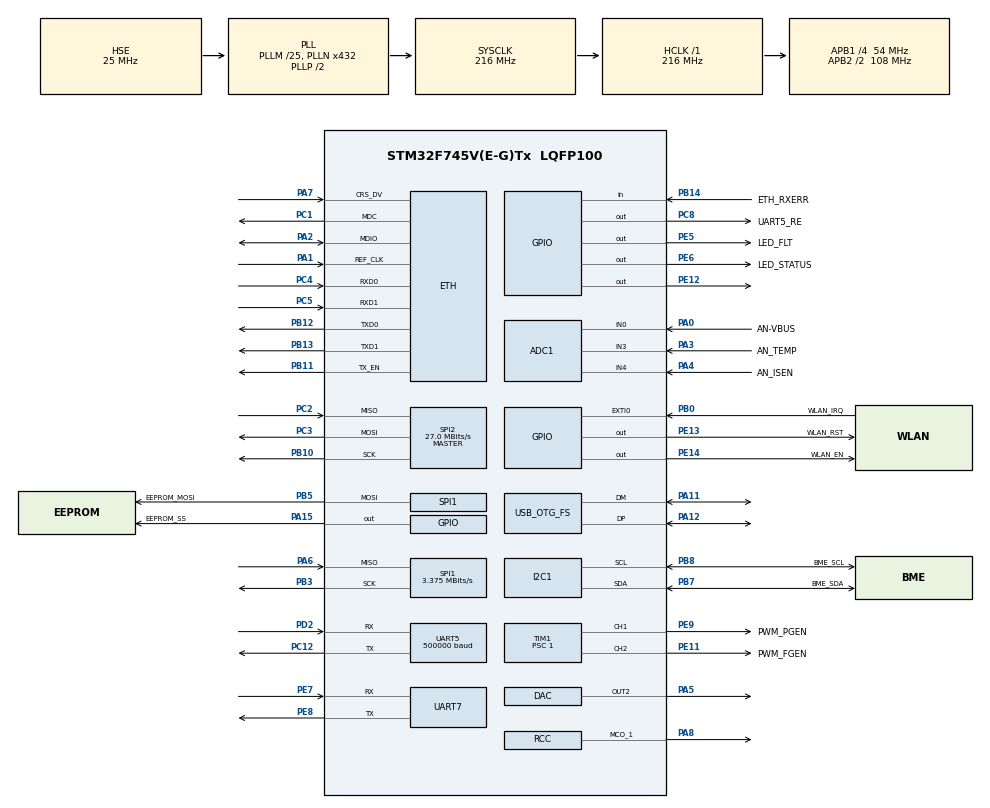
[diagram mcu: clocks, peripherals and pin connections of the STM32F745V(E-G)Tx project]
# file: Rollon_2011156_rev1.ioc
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ADC1.Channel-0\#ChannelRegularConversion=ADC_CHANNEL_0
ADC1.Channel-1\#ChannelRegularConversion=ADC_CHANNEL_3
ADC1.Channel-2\#ChannelRegularConversion=ADC_CHANNEL_4
ADC1.Channel-3\#ChannelRegularConversion=ADC_CHANNEL_TEMPSENSOR
ADC1.ContinuousConvMode=ENABLE
ADC1.DMAContinuousRequests=ENABLE
ADC1.EOCSelection=ADC_EOC_SEQ_CONV
ADC1.ExternalTrigConv=ADC_SOFTWARE_START
ADC1.InjNumberOfConversion=0
ADC1.NbrOfConversion=4
ADC1.NbrOfConversionFlag=1
ADC1.Rank-0\#ChannelRegularConversion=1
ADC1.Rank-1\#ChannelRegularConversion=2
ADC1.Rank-2\#ChannelRegularConversion=3
ADC1.Rank-3\#ChannelRegularConversion=4
ADC1.SamplingTime-0\#ChannelRegularConversion=ADC_SAMPLETIME_480CYCLES
ADC1.SamplingTime-1\#ChannelRegularConversion=ADC_SAMPLETIME_480CYCLES
ADC1.SamplingTime-2\#ChannelRegularConversion=ADC_SAMPLETIME_480CYCLES
ADC1.SamplingTime-3\#ChannelRegularConversion=ADC_SAMPLETIME_480CYCLES
ADC1.master=1
CORTEX_M7.ART_ACCELERATOR_ENABLE=0
CORTEX_M7.CPU_ICache=Enabled
CORTEX_M7.PREFETCH_ENABLE=0
CORTEX_M7.default_mode_Activation=0
Dma.ADC1.0.Direction=DMA_PERIPH_TO_MEMORY
Dma.ADC1.0.FIFOMode=DMA_FIFOMODE_DISABLE
Dma.ADC1.0.Instance=DMA2_Stream0
Dma.ADC1.0.MemDataAlignment=DMA_MDATAALIGN_HALFWORD
Dma.ADC1.0.MemInc=DMA_MINC_ENABLE
Dma.ADC1.0.Mode=DMA_CIRCULAR
Dma.ADC1.0.PeriphDataAlignment=DMA_PDATAALIGN_HALFWORD
Dma.ADC1.0.PeriphInc=DMA_PINC_DISABLE
Dma.ADC1.0.Priority=DMA_PRIORITY_LOW
Dma.Request0=ADC1
ETH.MACAddr=98\:80\:E1\:22\:00\:11
ETH.MediaInterface=HAL_ETH_RMII_MODE
I2C1.Analog_Filter=I2C_ANALOGFILTER_DISABLE
I2C1.Timing=0x00303D5D
LWIP.BSP.number=1
LWIP.GATEWAY_ADDRESS=192.168.010.001
LWIP.IP_ADDRESS=192.168.010.200
LWIP.LWIP_DHCP=0
LWIP.MEM_SIZE=4096
LWIP.NETMASK_ADDRESS=255.255.255.000
LWIP.PBUF_POOL_BUFSIZE=1560
LWIP.Version=v2.1.2_Cube
LWIP0.BSP.STBoard=false
LWIP0.BSP.api=BSP_COMPONENT_DRIVER
LWIP0.BSP.component=LAN8742
LWIP0.BSP.instance=LAN8742
LWIP0.BSP.name=Driver_PHY
LWIP0.BSP.semaphore=S_LAN8742
LWIP0.BSP.solution=LAN8742
Mcu.Family=STM32F7
Mcu.Name=STM32F745V(E-G)Tx
Mcu.Package=LQFP100
Mcu.UserConstants=PERIOD_T1,410;HPERIOD_T1,(PERIOD_T1/2);HPERIOD_PWR,((PERIOD_T1/10)*9)
NVIC.DMA2_Stream0_IRQn=true\:0\:0\:false\:false\:true\:false\:true\:true
NVIC.PriorityGroup=NVIC_PRIORITYGROUP_4
NVIC.TIM6_DAC_IRQn=true\:0\:0\:false\:false\:true\:true\:true\:true
NVIC.TIM7_IRQn=true\:0\:0\:false\:false\:true\:true\:true\:true
NVIC.UART5_IRQn=true\:0\:0\:false\:false\:true\:true\:true\:true
PA0/WKUP.GPIO_Label=AN-VBUS
PA0/WKUP.Signal=ADCx_IN0
PA1.Mode=RMII
PA1.Signal=ETH_REF_CLK
PA11.Mode=Device_Only
PA11.Signal=USB_OTG_FS_DM
PA12.Mode=Device_Only
PA12.Signal=USB_OTG_FS_DP
PA13.Mode=Serial_Wire
PA13.Signal=SYS_JTMS-SWDIO
PA14.Mode=Serial_Wire
PA14.Signal=SYS_JTCK-SWCLK
PA15.GPIO_Label=EEPROM_SS
PA15.Signal=GPIO_Output
PA2.Mode=RMII
PA2.Signal=ETH_MDIO
PA3.GPIO_Label=AN_TEMP
PA3.Signal=ADCx_IN3
PA4.GPIO_Label=AN_ISEN
PA4.Signal=ADCx_IN4
PA5.Signal=COMP_DAC2_group
PA6.Mode=Full_Duplex_Master
PA6.Signal=SPI1_MISO
PA7.Mode=RMII
PA7.Signal=ETH_CRS_DV
PA8.Mode=Clock-out-1
PA8.Signal=RCC_MCO_1
PB0.GPIO_Label=WLAN_IRQ
PB0.Signal=GPXTI0
PB10.Mode=Full_Duplex_Master
PB10.Signal=SPI2_SCK
PB11.Mode=RMII
PB11.Signal=ETH_TX_EN
PB12.Mode=RMII
PB12.Signal=ETH_TXD0
PB13.Mode=RMII
PB13.Signal=ETH_TXD1
PB14.GPIO_Label=ETH_RXERR
PB14.Signal=GPIO_Input
PB3.Mode=Full_Duplex_Master
PB3.Signal=SPI1_SCK
PB5.GPIO_Label=EEPROM_MOSI
PB5.Mode=Full_Duplex_Master
PB5.Signal=SPI1_MOSI
PB7.GPIO_Label=BME_SDA
PB7.Mode=I2C
PB7.Signal=I2C1_SDA
PB8.GPIO_Label=BME_SCL
PB8.Mode=I2C
PB8.Signal=I2C1_SCL
PC1.Mode=RMII
PC1.Signal=ETH_MDC
PC12.Mode=Asynchronous
PC12.Signal=UART5_TX
PC2.Mode=Full_Duplex_Master
PC2.Signal=SPI2_MISO
PC3.Mode=Full_Duplex_Master
PC3.Signal=SPI2_MOSI
PC4.Mode=RMII
PC4.Signal=ETH_RXD0
PC5.Mode=RMII
PC5.Signal=ETH_RXD1
PC8.GPIO_Label=UART5_RE
PC8.Signal=GPIO_Output
PD2.Mode=Asynchronous
PD2.Signal=UART5_RX
PE11.GPIO_Label=PWM_FGEN
PE11.Signal=S_TIM1_CH2
PE12.Signal=GPIO_Output
PE13.GPIO_Label=WLAN_RST
PE13.Signal=GPIO_Output
PE14.GPIO_Label=WLAN_EN
PE14.Signal=GPIO_Output
PE5.GPIO_Label=LED_FLT
PE5.Signal=GPIO_Output
PE6.GPIO_Label=LED_STATUS
PE6.Signal=GPIO_Output
PE7.Mode=Asynchronous
PE7.Signal=UART7_RX
PE8.Mode=Asynchronous
PE8.Signal=UART7_TX
PE9.GPIO_Label=PWM_PGEN
PE9.Signal=S_TIM1_CH1
PH0/OSC_IN.Mode=HSE-External-Clock-Source
PH0/OSC_IN.Signal=RCC_OSC_IN
PH1/OSC_OUT.Mode=HSE-External-Clock-Source
PH1/OSC_OUT.Signal=RCC_OSC_OUT
ProjectManager.HeapSize=0x2000
ProjectManager.StackSize=0x4000
ProjectManager.TargetToolchain=STM32CubeIDE
RCC.AHBFreq_Value=216000000
RCC.APB1CLKDivider=RCC_HCLK_DIV4
RCC.APB1Freq_Value=54000000
RCC.APB1TimFreq_Value=108000000
RCC.APB2CLKDivider=RCC_HCLK_DIV2
RCC.APB2Freq_Value=108000000
RCC.APB2TimFreq_Value=216000000
RCC.CortexFreq_Value=216000000
RCC.HCLKFreq_Value=216000000
RCC.HSE_VALUE=25000000
RCC.HSI_VALUE=16000000
RCC.I2C1CLockSelection=RCC_I2C1CLKSOURCE_HSI
RCC.LSE_VALUE=32768
RCC.PLL48CLockSelection=RCC_CLK48SOURCE_PLLSAIP
RCC.PLLM=25
RCC.PLLN=432
RCC.PLLQ=8
RCC.PLLSAIP=RCC_PLLSAIP_DIV4
RCC.SYSCLKFreq_VALUE=216000000
RCC.SYSCLKSource=RCC_SYSCLKSOURCE_PLLCLK
RCC.UART5CLockSelection=RCC_UART5CLKSOURCE_SYSCLK
RCC.UART7CLockSelection=RCC_UART7CLKSOURCE_SYSCLK
RCC.USBFreq_Value=48000000
RCC.VCOOutputFreq_Value=432000000
SH.ADCx_IN0.0=ADC1_IN0,IN0
SH.ADCx_IN3.0=ADC1_IN3,IN3
SH.ADCx_IN4.0=ADC1_IN4,IN4
SH.COMP_DAC2_group.0=DAC_OUT2,DAC_OUT2
SH.S_TIM1_CH1.0=TIM1_CH1,PWM Generation1 CH1
SH.S_TIM1_CH2.0=TIM1_CH2,PWM Generation2 CH2
SPI1.BaudRatePrescaler=SPI_BAUDRATEPRESCALER_32
SPI1.CalculateBaudRate=3.375 MBits/s
SPI1.DataSize=SPI_DATASIZE_8BIT
SPI1.Direction=SPI_DIRECTION_2LINES
SPI1.Mode=SPI_MODE_MASTER
SPI1.VirtualType=VM_MASTER
SPI2.BaudRatePrescaler=SPI_BAUDRATEPRESCALER_2
SPI2.CalculateBaudRate=27.0 MBits/s
SPI2.Direction=SPI_DIRECTION_2LINES
SPI2.Mode=SPI_MODE_MASTER
SPI2.VirtualType=VM_MASTER
STMicroelectronics.X-CUBE-EEPRMA1.4.1.0.EEPROMCcBoardOoPartJjM95JjM95XX=true
STMicroelectronics.X-CUBE-EEPRMA1.4.1.0.EEPROMCcBoardOoPartJjM95P32JjM95P32=true
TIM1.Channel-PWM\ Generation1\ CH1=TIM_CHANNEL_1
TIM1.Channel-PWM\ Generation2\ CH2=TIM_CHANNEL_2
TIM1.OCFastMode_PWM-PWM\ Generation2\ CH2=TIM_OCFAST_ENABLE
TIM1.Period=PERIOD_T1
TIM1.Prescaler=1
TIM1.Pulse=HPERIOD_T1
TIM1.Pulse-PWM\ Generation1\ CH1=HPERIOD_PWR
TIM1.Pulse-PWM\ Generation2\ CH2=HPERIOD_T1
TIM4.Channel-Output\ Compare1\ No\ Output=TIM_CHANNEL_1
TIM4.OCMode_1=TIM_OCMODE_ACTIVE
TIM4.Period=4999
TIM4.Prescaler=199
TIM4.Pulse-Output\ Compare1\ No\ Output=2000
TIM6.Period=4999
TIM6.Prescaler=199
TIM6.TIM_MasterOutputTrigger=TIM_TRGO_UPDATE
TIM7.Period=100
TIM7.Prescaler=18000
TIM8.Period=4999
TIM8.Prescaler=199
TIM8.TIM_MasterOutputTrigger=TIM_TRGO_UPDATE
UART5.BaudRate=500000
UART5.DMADisableonRxErrorParam=UART_ADVFEATURE_DMA_DISABLEONRXERROR
UART5.DataInvertParam=UART_ADVFEATURE_DATAINV_DISABLE
UART5.OverrunDisableParam=UART_ADVFEATURE_OVERRUN_DISABLE
UART5.RxPinLevelInvertParam=UART_ADVFEATURE_RXINV_ENABLE
UART5.TxPinLevelInvertParam=UART_ADVFEATURE_TXINV_ENABLE
USB_OTG_FS.VirtualMode=Device_Only
VP_ADC1_TempSens_Input.Mode=IN-TempSens
VP_CRC_VS_CRC.Mode=CRC_Activate
VP_LWIP_VS_Enabled.Mode=Enabled
VP_RTC_VS_RTC_Activate.Mode=RTC_Enabled
VP_STMicroelectronics.X-CUBE-EEPRMA1_VS_BoardOoPartJjEEPROM_4.1.0_4.1.0.Mode=BoardOoPartJjEEPROM
VP_TIM1_VS_ClockSourceINT.Mode=Internal
VP_TIM4_VS_ClockSourceINT.Mode=Internal
VP_TIM4_VS_no_output1.Mode=Output Compare1 No Output
VP_TIM6_VS_ClockSourceINT.Mode=Enable_Timer
VP_TIM7_VS_ClockSourceINT.Mode=Enable_Timer
VP_TIM8_VS_ClockSourceINT.Mode=Internal
board=custom

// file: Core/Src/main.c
/* USER CODE BEGIN Header */
/**
  ******************************************************************************
  * @file           : main.c
  * @brief          : Main program body
  ******************************************************************************
  * @attention
  *
  * Copyright (c) 2023 STMicroelectronics.
  * All rights reserved.
  *
  * This software is licensed under terms that can be found in the LICENSE file
  * in the root directory of this software component.
  * If no LICENSE file comes with this software, it is provided AS-IS.
  *
  ******************************************************************************
  */
/* USER CODE END Header */
#include "main.h"
#include "lwip.h"

ADC_HandleTypeDef hadc1;
DMA_HandleTypeDef hdma_adc1;

CRC_HandleTypeDef hcrc;

DAC_HandleTypeDef hdac;

I2C_HandleTypeDef hi2c1;

RTC_HandleTypeDef hrtc;

SPI_HandleTypeDef hspi1;
SPI_HandleTypeDef hspi2;

TIM_HandleTypeDef htim1;
TIM_HandleTypeDef htim4;
TIM_HandleTypeDef htim6;
TIM_HandleTypeDef htim7;
TIM_HandleTypeDef htim8;

UART_HandleTypeDef huart5;
UART_HandleTypeDef huart7;

PCD_HandleTypeDef hpcd_USB_OTG_FS;

void SystemClock_Config(void);
static void MX_GPIO_Init(void);
static void MX_DMA_Init(void);
static void MX_RTC_Init(void);
static void MX_TIM1_Init(void);
static void MX_TIM4_Init(void);
static void MX_TIM8_Init(void);
static void MX_CRC_Init(void);
static void MX_I2C1_Init(void);
static void MX_SPI1_Init(void);
static void MX_SPI2_Init(void);
static void MX_UART7_Init(void);
static void MX_ADC1_Init(void);
static void MX_TIM6_Init(void);
static void MX_TIM7_Init(void);
static void MX_DAC_Init(void);
static void MX_UART5_Init(void);
static void MX_USB_OTG_FS_PCD_Init(void);

int main(void)
{

  /* Enable I-Cache---------------------------------------------------------*/
  SCB_EnableICache();

  /* MCU Configuration--------------------------------------------------------*/

  /* Reset of all peripherals, Initializes the Flash interface and the Systick. */
  HAL_Init();

  /* Configure the system clock */
  SystemClock_Config();

  /* Initialize all configured peripherals */
  MX_GPIO_Init();
  MX_DMA_Init();
  MX_RTC_Init();
  MX_TIM1_Init();
  MX_TIM4_Init();
  MX_TIM8_Init();
  MX_CRC_Init();
  MX_I2C1_Init();
  MX_SPI1_Init();
  MX_SPI2_Init();
  MX_UART7_Init();
  MX_ADC1_Init();
  MX_TIM6_Init();
  MX_TIM7_Init();
  MX_DAC_Init();
  MX_UART5_Init();
  MX_USB_OTG_FS_PCD_Init();
  MX_LWIP_Init();
  /* USER CODE BEGIN 2 */
  Rollon_Init();
  /* USER CODE END 2 */

  /* Infinite loop */
  /* USER CODE BEGIN WHILE */
  while (1)
  {
	  Rollon_Loop();
    /* USER CODE END WHILE */

  }
}

void SystemClock_Config(void)
{
  RCC_OscInitTypeDef RCC_OscInitStruct = {0};
  RCC_ClkInitTypeDef RCC_ClkInitStruct = {0};

  /** Configure the main internal regulator output voltage
  */
  __HAL_RCC_PWR_CLK_ENABLE();
  __HAL_PWR_VOLTAGESCALING_CONFIG(PWR_REGULATOR_VOLTAGE_SCALE1);

  /** Initializes the RCC Oscillators according to the specified parameters
  * in the RCC_OscInitTypeDef structure.
  */
  RCC_OscInitStruct.OscillatorType = RCC_OSCILLATORTYPE_HSI|RCC_OSCILLATORTYPE_LSI
                              |RCC_OSCILLATORTYPE_HSE;
  RCC_OscInitStruct.HSEState = RCC_HSE_BYPASS;
  RCC_OscInitStruct.HSIState = RCC_HSI_ON;
  RCC_OscInitStruct.HSICalibrationValue = RCC_HSICALIBRATION_DEFAULT;
  RCC_OscInitStruct.LSIState = RCC_LSI_ON;
  RCC_OscInitStruct.PLL.PLLState = RCC_PLL_ON;
  RCC_OscInitStruct.PLL.PLLSource = RCC_PLLSOURCE_HSE;
  RCC_OscInitStruct.PLL.PLLM = 25;
  RCC_OscInitStruct.PLL.PLLN = 432;
  RCC_OscInitStruct.PLL.PLLP = RCC_PLLP_DIV2;
  RCC_OscInitStruct.PLL.PLLQ = 8;
  if (HAL_RCC_OscConfig(&RCC_OscInitStruct) != HAL_OK)
  {
    Error_Handler();
  }

  /** Activate the Over-Drive mode
  */
  if (HAL_PWREx_EnableOverDrive() != HAL_OK)
  {
    Error_Handler();
  }

  /** Initializes the CPU, AHB and APB buses clocks
  */
  RCC_ClkInitStruct.ClockType = RCC_CLOCKTYPE_HCLK|RCC_CLOCKTYPE_SYSCLK
                              |RCC_CLOCKTYPE_PCLK1|RCC_CLOCKTYPE_PCLK2;
  RCC_ClkInitStruct.SYSCLKSource = RCC_SYSCLKSOURCE_PLLCLK;
  RCC_ClkInitStruct.AHBCLKDivider = RCC_SYSCLK_DIV1;
  RCC_ClkInitStruct.APB1CLKDivider = RCC_HCLK_DIV4;
  RCC_ClkInitStruct.APB2CLKDivider = RCC_HCLK_DIV2;

  if (HAL_RCC_ClockConfig(&RCC_ClkInitStruct, FLASH_LATENCY_7) != HAL_OK)
  {
    Error_Handler();
  }
  HAL_RCC_MCOConfig(RCC_MCO1, RCC_MCO1SOURCE_HSI, RCC_MCODIV_1);
}

static void MX_ADC1_Init(void)
{

  ADC_ChannelConfTypeDef sConfig = {0};

  /** Configure the global features of the ADC (Clock, Resolution, Data Alignment and number of conversion)
  */
  hadc1.Instance = ADC1;
  hadc1.Init.ClockPrescaler = ADC_CLOCK_SYNC_PCLK_DIV4;
  hadc1.Init.Resolution = ADC_RESOLUTION_12B;
  hadc1.Init.ScanConvMode = ADC_SCAN_ENABLE;
  hadc1.Init.ContinuousConvMode = ENABLE;
  hadc1.Init.DiscontinuousConvMode = DISABLE;
  hadc1.Init.ExternalTrigConvEdge = ADC_EXTERNALTRIGCONVEDGE_NONE;
  hadc1.Init.ExternalTrigConv = ADC_SOFTWARE_START;
  hadc1.Init.DataAlign = ADC_DATAALIGN_RIGHT;
  hadc1.Init.NbrOfConversion = 4;
  hadc1.Init.DMAContinuousRequests = ENABLE;
  hadc1.Init.EOCSelection = ADC_EOC_SEQ_CONV;
  if (HAL_ADC_Init(&hadc1) != HAL_OK)
  {
    Error_Handler();
  }

  /** Configure for the selected ADC regular channel its corresponding rank in the sequencer and its sample time.
  */
  sConfig.Channel = ADC_CHANNEL_0;
  sConfig.Rank = ADC_REGULAR_RANK_1;
  sConfig.SamplingTime = ADC_SAMPLETIME_480CYCLES;
  if (HAL_ADC_ConfigChannel(&hadc1, &sConfig) != HAL_OK)
  {
    Error_Handler();
  }

  /** Configure for the selected ADC regular channel its corresponding rank in the sequencer and its sample time.
  */
  sConfig.Channel = ADC_CHANNEL_3;
  sConfig.Rank = ADC_REGULAR_RANK_2;
  if (HAL_ADC_ConfigChannel(&hadc1, &sConfig) != HAL_OK)
  {
    Error_Handler();
  }

  /** Configure for the selected ADC regular channel its corresponding rank in the sequencer and its sample time.
  */
  sConfig.Channel = ADC_CHANNEL_4;
  sConfig.Rank = ADC_REGULAR_RANK_3;
  if (HAL_ADC_ConfigChannel(&hadc1, &sConfig) != HAL_OK)
  {
    Error_Handler();
  }

  /** Configure for the selected ADC regular channel its corresponding rank in the sequencer and its sample time.
  */
  sConfig.Channel = ADC_CHANNEL_TEMPSENSOR;
  sConfig.Rank = ADC_REGULAR_RANK_4;
  if (HAL_ADC_ConfigChannel(&hadc1, &sConfig) != HAL_OK)
  {
    Error_Handler();
  }

}

static void MX_CRC_Init(void)
{

  hcrc.Instance = CRC;
  hcrc.Init.DefaultPolynomialUse = DEFAULT_POLYNOMIAL_ENABLE;
  hcrc.Init.DefaultInitValueUse = DEFAULT_INIT_VALUE_ENABLE;
  hcrc.Init.InputDataInversionMode = CRC_INPUTDATA_INVERSION_NONE;
  hcrc.Init.OutputDataInversionMode = CRC_OUTPUTDATA_INVERSION_DISABLE;
  hcrc.InputDataFormat = CRC_INPUTDATA_FORMAT_BYTES;
  if (HAL_CRC_Init(&hcrc) != HAL_OK)
  {
    Error_Handler();
  }

}

static void MX_DAC_Init(void)
{

  DAC_ChannelConfTypeDef sConfig = {0};

  /** DAC Initialization
  */
  hdac.Instance = DAC;
  if (HAL_DAC_Init(&hdac) != HAL_OK)
  {
    Error_Handler();
  }

  /** DAC channel OUT2 config
  */
  sConfig.DAC_Trigger = DAC_TRIGGER_NONE;
  sConfig.DAC_OutputBuffer = DAC_OUTPUTBUFFER_ENABLE;
  if (HAL_DAC_ConfigChannel(&hdac, &sConfig, DAC_CHANNEL_2) != HAL_OK)
  {
    Error_Handler();
  }

}

static void MX_I2C1_Init(void)
{

  hi2c1.Instance = I2C1;
  hi2c1.Init.Timing = 0x00303D5D;
  hi2c1.Init.OwnAddress1 = 0;
  hi2c1.Init.AddressingMode = I2C_ADDRESSINGMODE_7BIT;
  hi2c1.Init.DualAddressMode = I2C_DUALADDRESS_DISABLE;
  hi2c1.Init.OwnAddress2 = 0;
  hi2c1.Init.OwnAddress2Masks = I2C_OA2_NOMASK;
  hi2c1.Init.GeneralCallMode = I2C_GENERALCALL_DISABLE;
  hi2c1.Init.NoStretchMode = I2C_NOSTRETCH_DISABLE;
  if (HAL_I2C_Init(&hi2c1) != HAL_OK)
  {
    Error_Handler();
  }

  /** Configure Analogue filter
  */
  if (HAL_I2CEx_ConfigAnalogFilter(&hi2c1, I2C_ANALOGFILTER_DISABLE) != HAL_OK)
  {
    Error_Handler();
  }

  /** Configure Digital filter
  */
  if (HAL_I2CEx_ConfigDigitalFilter(&hi2c1, 0) != HAL_OK)
  {
    Error_Handler();
  }

}

static void MX_RTC_Init(void)
{

  /** Initialize RTC Only
  */
  hrtc.Instance = RTC;
  hrtc.Init.HourFormat = RTC_HOURFORMAT_24;
  hrtc.Init.AsynchPrediv = 127;
  hrtc.Init.SynchPrediv = 255;
  hrtc.Init.OutPut = RTC_OUTPUT_DISABLE;
  hrtc.Init.OutPutPolarity = RTC_OUTPUT_POLARITY_HIGH;
  hrtc.Init.OutPutType = RTC_OUTPUT_TYPE_OPENDRAIN;
  if (HAL_RTC_Init(&hrtc) != HAL_OK)
  {
    Error_Handler();
  }

}

static void MX_SPI1_Init(void)
{

  /* SPI1 parameter configuration*/
  hspi1.Instance = SPI1;
  hspi1.Init.Mode = SPI_MODE_MASTER;
  hspi1.Init.Direction = SPI_DIRECTION_2LINES;
  hspi1.Init.DataSize = SPI_DATASIZE_8BIT;
  hspi1.Init.CLKPolarity = SPI_POLARITY_LOW;
  hspi1.Init.CLKPhase = SPI_PHASE_1EDGE;
  hspi1.Init.NSS = SPI_NSS_SOFT;
  hspi1.Init.BaudRatePrescaler = SPI_BAUDRATEPRESCALER_32;
  hspi1.Init.FirstBit = SPI_FIRSTBIT_MSB;
  hspi1.Init.TIMode = SPI_TIMODE_DISABLE;
  hspi1.Init.CRCCalculation = SPI_CRCCALCULATION_DISABLE;
  hspi1.Init.CRCPolynomial = 7;
  hspi1.Init.CRCLength = SPI_CRC_LENGTH_DATASIZE;
  hspi1.Init.NSSPMode = SPI_NSS_PULSE_ENABLE;
  if (HAL_SPI_Init(&hspi1) != HAL_OK)
  {
    Error_Handler();
  }

}

static void MX_SPI2_Init(void)
{

  /* SPI2 parameter configuration*/
  hspi2.Instance = SPI2;
  hspi2.Init.Mode = SPI_MODE_MASTER;
  hspi2.Init.Direction = SPI_DIRECTION_2LINES;
  hspi2.Init.DataSize = SPI_DATASIZE_4BIT;
  hspi2.Init.CLKPolarity = SPI_POLARITY_LOW;
  hspi2.Init.CLKPhase = SPI_PHASE_1EDGE;
  hspi2.Init.NSS = SPI_NSS_SOFT;
  hspi2.Init.BaudRatePrescaler = SPI_BAUDRATEPRESCALER_2;
  hspi2.Init.FirstBit = SPI_FIRSTBIT_MSB;
  hspi2.Init.TIMode = SPI_TIMODE_DISABLE;
  hspi2.Init.CRCCalculation = SPI_CRCCALCULATION_DISABLE;
  hspi2.Init.CRCPolynomial = 7;
  hspi2.Init.CRCLength = SPI_CRC_LENGTH_DATASIZE;
  hspi2.Init.NSSPMode = SPI_NSS_PULSE_ENABLE;
  if (HAL_SPI_Init(&hspi2) != HAL_OK)
  {
    Error_Handler();
  }

}

static void MX_TIM1_Init(void)
{

  TIM_ClockConfigTypeDef sClockSourceConfig = {0};
  TIM_MasterConfigTypeDef sMasterConfig = {0};
  TIM_OC_InitTypeDef sConfigOC = {0};
  TIM_BreakDeadTimeConfigTypeDef sBreakDeadTimeConfig = {0};

  htim1.Instance = TIM1;
  htim1.Init.Prescaler = 1;
  htim1.Init.CounterMode = TIM_COUNTERMODE_UP;
  htim1.Init.Period = PERIOD_T1;
  htim1.Init.ClockDivision = TIM_CLOCKDIVISION_DIV1;
  htim1.Init.RepetitionCounter = 0;
  htim1.Init.AutoReloadPreload = TIM_AUTORELOAD_PRELOAD_DISABLE;
  if (HAL_TIM_Base_Init(&htim1) != HAL_OK)
  {
    Error_Handler();
  }
  sClockSourceConfig.ClockSource = TIM_CLOCKSOURCE_INTERNAL;
  if (HAL_TIM_ConfigClockSource(&htim1, &sClockSourceConfig) != HAL_OK)
  {
    Error_Handler();
  }
  if (HAL_TIM_PWM_Init(&htim1) != HAL_OK)
  {
    Error_Handler();
  }
  sMasterConfig.MasterOutputTrigger = TIM_TRGO_RESET;
  sMasterConfig.MasterOutputTrigger2 = TIM_TRGO2_RESET;
  sMasterConfig.MasterSlaveMode = TIM_MASTERSLAVEMODE_DISABLE;
  if (HAL_TIMEx_MasterConfigSynchronization(&htim1, &sMasterConfig) != HAL_OK)
  {
    Error_Handler();
  }
  sConfigOC.OCMode = TIM_OCMODE_PWM1;
  sConfigOC.Pulse = HPERIOD_PWR;
  sConfigOC.OCPolarity = TIM_OCPOLARITY_HIGH;
  sConfigOC.OCNPolarity = TIM_OCNPOLARITY_HIGH;
  sConfigOC.OCFastMode = TIM_OCFAST_DISABLE;
  sConfigOC.OCIdleState = TIM_OCIDLESTATE_RESET;
  sConfigOC.OCNIdleState = TIM_OCNIDLESTATE_RESET;
  if (HAL_TIM_PWM_ConfigChannel(&htim1, &sConfigOC, TIM_CHANNEL_1) != HAL_OK)
  {
    Error_Handler();
  }
  sConfigOC.Pulse = HPERIOD_T1;
  sConfigOC.OCFastMode = TIM_OCFAST_ENABLE;
  if (HAL_TIM_PWM_ConfigChannel(&htim1, &sConfigOC, TIM_CHANNEL_2) != HAL_OK)
  {
    Error_Handler();
  }
  sBreakDeadTimeConfig.OffStateRunMode = TIM_OSSR_DISABLE;
  sBreakDeadTimeConfig.OffStateIDLEMode = TIM_OSSI_DISABLE;
  sBreakDeadTimeConfig.LockLevel = TIM_LOCKLEVEL_OFF;
  sBreakDeadTimeConfig.DeadTime = 0;
  sBreakDeadTimeConfig.BreakState = TIM_BREAK_DISABLE;
  sBreakDeadTimeConfig.BreakPolarity = TIM_BREAKPOLARITY_HIGH;
  sBreakDeadTimeConfig.BreakFilter = 0;
  sBreakDeadTimeConfig.Break2State = TIM_BREAK2_DISABLE;
  sBreakDeadTimeConfig.Break2Polarity = TIM_BREAK2POLARITY_HIGH;
  sBreakDeadTimeConfig.Break2Filter = 0;
  sBreakDeadTimeConfig.AutomaticOutput = TIM_AUTOMATICOUTPUT_DISABLE;
  if (HAL_TIMEx_ConfigBreakDeadTime(&htim1, &sBreakDeadTimeConfig) != HAL_OK)
  {
    Error_Handler();
  }
  HAL_TIM_MspPostInit(&htim1);

}

static void MX_TIM4_Init(void)
{

  TIM_ClockConfigTypeDef sClockSourceConfig = {0};
  TIM_MasterConfigTypeDef sMasterConfig = {0};
  TIM_OC_InitTypeDef sConfigOC = {0};

  htim4.Instance = TIM4;
  htim4.Init.Prescaler = 199;
  htim4.Init.CounterMode = TIM_COUNTERMODE_UP;
  htim4.Init.Period = 4999;
  htim4.Init.ClockDivision = TIM_CLOCKDIVISION_DIV1;
  htim4.Init.AutoReloadPreload = TIM_AUTORELOAD_PRELOAD_DISABLE;
  if (HAL_TIM_Base_Init(&htim4) != HAL_OK)
  {
    Error_Handler();
  }
  sClockSourceConfig.ClockSource = TIM_CLOCKSOURCE_INTERNAL;
  if (HAL_TIM_ConfigClockSource(&htim4, &sClockSourceConfig) != HAL_OK)
  {
    Error_Handler();
  }
  if (HAL_TIM_OC_Init(&htim4) != HAL_OK)
  {
    Error_Handler();
  }
  sMasterConfig.MasterOutputTrigger = TIM_TRGO_RESET;
  sMasterConfig.MasterSlaveMode = TIM_MASTERSLAVEMODE_DISABLE;
  if (HAL_TIMEx_MasterConfigSynchronization(&htim4, &sMasterConfig) != HAL_OK)
  {
    Error_Handler();
  }
  sConfigOC.OCMode = TIM_OCMODE_ACTIVE;
  sConfigOC.Pulse = 2000;
  sConfigOC.OCPolarity = TIM_OCPOLARITY_HIGH;
  sConfigOC.OCFastMode = TIM_OCFAST_DISABLE;
  if (HAL_TIM_OC_ConfigChannel(&htim4, &sConfigOC, TIM_CHANNEL_1) != HAL_OK)
  {
    Error_Handler();
  }

}

static void MX_TIM6_Init(void)
{

  TIM_MasterConfigTypeDef sMasterConfig = {0};

  htim6.Instance = TIM6;
  htim6.Init.Prescaler = 199;
  htim6.Init.CounterMode = TIM_COUNTERMODE_UP;
  htim6.Init.Period = 4999;
  htim6.Init.AutoReloadPreload = TIM_AUTORELOAD_PRELOAD_DISABLE;
  if (HAL_TIM_Base_Init(&htim6) != HAL_OK)
  {
    Error_Handler();
  }
  sMasterConfig.MasterOutputTrigger = TIM_TRGO_UPDATE;
  sMasterConfig.MasterSlaveMode = TIM_MASTERSLAVEMODE_DISABLE;
  if (HAL_TIMEx_MasterConfigSynchronization(&htim6, &sMasterConfig) != HAL_OK)
  {
    Error_Handler();
  }

}

static void MX_TIM7_Init(void)
{

  TIM_MasterConfigTypeDef sMasterConfig = {0};

  htim7.Instance = TIM7;
  htim7.Init.Prescaler = 18000;
  htim7.Init.CounterMode = TIM_COUNTERMODE_UP;
  htim7.Init.Period = 100;
  htim7.Init.AutoReloadPreload = TIM_AUTORELOAD_PRELOAD_DISABLE;
  if (HAL_TIM_Base_Init(&htim7) != HAL_OK)
  {
    Error_Handler();
  }
  sMasterConfig.MasterOutputTrigger = TIM_TRGO_RESET;
  sMasterConfig.MasterSlaveMode = TIM_MASTERSLAVEMODE_DISABLE;
  if (HAL_TIMEx_MasterConfigSynchronization(&htim7, &sMasterConfig) != HAL_OK)
  {
    Error_Handler();
  }

}

static void MX_TIM8_Init(void)
{

  TIM_ClockConfigTypeDef sClockSourceConfig = {0};
  TIM_MasterConfigTypeDef sMasterConfig = {0};

  htim8.Instance = TIM8;
  htim8.Init.Prescaler = 199;
  htim8.Init.CounterMode = TIM_COUNTERMODE_UP;
  htim8.Init.Period = 4999;
  htim8.Init.ClockDivision = TIM_CLOCKDIVISION_DIV1;
  htim8.Init.RepetitionCounter = 0;
  htim8.Init.AutoReloadPreload = TIM_AUTORELOAD_PRELOAD_DISABLE;
  if (HAL_TIM_Base_Init(&htim8) != HAL_OK)
  {
    Error_Handler();
  }
  sClockSourceConfig.ClockSource = TIM_CLOCKSOURCE_INTERNAL;
  if (HAL_TIM_ConfigClockSource(&htim8, &sClockSourceConfig) != HAL_OK)
  {
    Error_Handler();
  }
  sMasterConfig.MasterOutputTrigger = TIM_TRGO_UPDATE;
  sMasterConfig.MasterOutputTrigger2 = TIM_TRGO2_RESET;
  sMasterConfig.MasterSlaveMode = TIM_MASTERSLAVEMODE_DISABLE;
  if (HAL_TIMEx_MasterConfigSynchronization(&htim8, &sMasterConfig) != HAL_OK)
  {
    Error_Handler();
  }

}

static void MX_UART5_Init(void)
{

  huart5.Instance = UART5;
  huart5.Init.BaudRate = 500000;
  huart5.Init.WordLength = UART_WORDLENGTH_8B;
  huart5.Init.StopBits = UART_STOPBITS_1;
  huart5.Init.Parity = UART_PARITY_NONE;
  huart5.Init.Mode = UART_MODE_TX_RX;
  huart5.Init.HwFlowCtl = UART_HWCONTROL_NONE;
  huart5.Init.OverSampling = UART_OVERSAMPLING_16;
  huart5.Init.OneBitSampling = UART_ONE_BIT_SAMPLE_DISABLE;
  huart5.AdvancedInit.AdvFeatureInit = UART_ADVFEATURE_TXINVERT_INIT|UART_ADVFEATURE_RXINVERT_INIT
                              |UART_ADVFEATURE_RXOVERRUNDISABLE_INIT|UART_ADVFEATURE_DMADISABLEONERROR_INIT;
  huart5.AdvancedInit.TxPinLevelInvert = UART_ADVFEATURE_TXINV_ENABLE;
  huart5.AdvancedInit.RxPinLevelInvert = UART_ADVFEATURE_RXINV_ENABLE;
  huart5.AdvancedInit.OverrunDisable = UART_ADVFEATURE_OVERRUN_DISABLE;
  huart5.AdvancedInit.DMADisableonRxError = UART_ADVFEATURE_DMA_DISABLEONRXERROR;
  if (HAL_UART_Init(&huart5) != HAL_OK)
  {
    Error_Handler();
  }

}

static void MX_UART7_Init(void)
{

  huart7.Instance = UART7;
  huart7.Init.BaudRate = 115200;
  huart7.Init.WordLength = UART_WORDLENGTH_8B;
  huart7.Init.StopBits = UART_STOPBITS_1;
  huart7.Init.Parity = UART_PARITY_NONE;
  huart7.Init.Mode = UART_MODE_TX_RX;
  huart7.Init.HwFlowCtl = UART_HWCONTROL_NONE;
  huart7.Init.OverSampling = UART_OVERSAMPLING_16;
  huart7.Init.OneBitSampling = UART_ONE_BIT_SAMPLE_DISABLE;
  huart7.AdvancedInit.AdvFeatureInit = UART_ADVFEATURE_NO_INIT;
  if (HAL_UART_Init(&huart7) != HAL_OK)
  {
    Error_Handler();
  }

}

static void MX_USB_OTG_FS_PCD_Init(void)
{

  hpcd_USB_OTG_FS.Instance = USB_OTG_FS;
  hpcd_USB_OTG_FS.Init.dev_endpoints = 6;
  hpcd_USB_OTG_FS.Init.speed = PCD_SPEED_FULL;
  hpcd_USB_OTG_FS.Init.dma_enable = DISABLE;
  hpcd_USB_OTG_FS.Init.phy_itface = PCD_PHY_EMBEDDED;
  hpcd_USB_OTG_FS.Init.Sof_enable = DISABLE;
  hpcd_USB_OTG_FS.Init.low_power_enable = DISABLE;
  hpcd_USB_OTG_FS.Init.lpm_enable = DISABLE;
  hpcd_USB_OTG_FS.Init.vbus_sensing_enable = DISABLE;
  hpcd_USB_OTG_FS.Init.use_dedicated_ep1 = DISABLE;
  if (HAL_PCD_Init(&hpcd_USB_OTG_FS) != HAL_OK)
  {
    Error_Handler();
  }

}

static void MX_DMA_Init(void)
{

  /* DMA controller clock enable */
  __HAL_RCC_DMA2_CLK_ENABLE();

  /* DMA interrupt init */
  /* DMA2_Stream0_IRQn interrupt configuration */
  HAL_NVIC_SetPriority(DMA2_Stream0_IRQn, 0, 0);
  HAL_NVIC_EnableIRQ(DMA2_Stream0_IRQn);

}

static void MX_GPIO_Init(void)
{
  GPIO_InitTypeDef GPIO_InitStruct = {0};

  /* GPIO Ports Clock Enable */
  __HAL_RCC_GPIOE_CLK_ENABLE();
  __HAL_RCC_GPIOH_CLK_ENABLE();
  __HAL_RCC_GPIOC_CLK_ENABLE();
  __HAL_RCC_GPIOA_CLK_ENABLE();
  __HAL_RCC_GPIOB_CLK_ENABLE();
  __HAL_RCC_GPIOD_CLK_ENABLE();

  /*Configure GPIO pin Output Level */
  HAL_GPIO_WritePin(GPIOE, LED_FLT_Pin|LED_STATUS_Pin|GPIO_PIN_12|WLAN_RST_Pin
                          |WLAN_EN_Pin, GPIO_PIN_RESET);

  /*Configure GPIO pin Output Level */
  HAL_GPIO_WritePin(UART5_RE_GPIO_Port, UART5_RE_Pin, GPIO_PIN_RESET);

  /*Configure GPIO pin Output Level */
  HAL_GPIO_WritePin(EEPROM_SS_GPIO_Port, EEPROM_SS_Pin, GPIO_PIN_RESET);

  /*Configure GPIO pins : LED_FLT_Pin LED_STATUS_Pin PE12 WLAN_RST_Pin
                           WLAN_EN_Pin */
  GPIO_InitStruct.Pin = LED_FLT_Pin|LED_STATUS_Pin|GPIO_PIN_12|WLAN_RST_Pin
                          |WLAN_EN_Pin;
  GPIO_InitStruct.Mode = GPIO_MODE_OUTPUT_PP;
  GPIO_InitStruct.Pull = GPIO_NOPULL;
  GPIO_InitStruct.Speed = GPIO_SPEED_FREQ_LOW;
  HAL_GPIO_Init(GPIOE, &GPIO_InitStruct);

  /*Configure GPIO pin : WLAN_IRQ_Pin */
  GPIO_InitStruct.Pin = WLAN_IRQ_Pin;
  GPIO_InitStruct.Mode = GPIO_MODE_IT_RISING;
  GPIO_InitStruct.Pull = GPIO_NOPULL;
  HAL_GPIO_Init(WLAN_IRQ_GPIO_Port, &GPIO_InitStruct);

  /*Configure GPIO pin : ETH_RXERR_Pin */
  GPIO_InitStruct.Pin = ETH_RXERR_Pin;
  GPIO_InitStruct.Mode = GPIO_MODE_INPUT;
  GPIO_InitStruct.Pull = GPIO_NOPULL;
  HAL_GPIO_Init(ETH_RXERR_GPIO_Port, &GPIO_InitStruct);

  /*Configure GPIO pin : UART5_RE_Pin */
  GPIO_InitStruct.Pin = UART5_RE_Pin;
  GPIO_InitStruct.Mode = GPIO_MODE_OUTPUT_PP;
  GPIO_InitStruct.Pull = GPIO_NOPULL;
  GPIO_InitStruct.Speed = GPIO_SPEED_FREQ_LOW;
  HAL_GPIO_Init(UART5_RE_GPIO_Port, &GPIO_InitStruct);

  /*Configure GPIO pin : PA8 */
  GPIO_InitStruct.Pin = GPIO_PIN_8;
  GPIO_InitStruct.Mode = GPIO_MODE_AF_PP;
  GPIO_InitStruct.Pull = GPIO_NOPULL;
  GPIO_InitStruct.Speed = GPIO_SPEED_FREQ_LOW;
  GPIO_InitStruct.Alternate = GPIO_AF0_MCO;
  HAL_GPIO_Init(GPIOA, &GPIO_InitStruct);

  /*Configure GPIO pin : EEPROM_SS_Pin */
  GPIO_InitStruct.Pin = EEPROM_SS_Pin;
  GPIO_InitStruct.Mode = GPIO_MODE_OUTPUT_PP;
  GPIO_InitStruct.Pull = GPIO_NOPULL;
  GPIO_InitStruct.Speed = GPIO_SPEED_FREQ_LOW;
  HAL_GPIO_Init(EEPROM_SS_GPIO_Port, &GPIO_InitStruct);

}

void Error_Handler(void)
{
  __disable_irq();
  while (1)
  {
  }
}
